VERSION ""

NS_ :

BS_:

BU_:

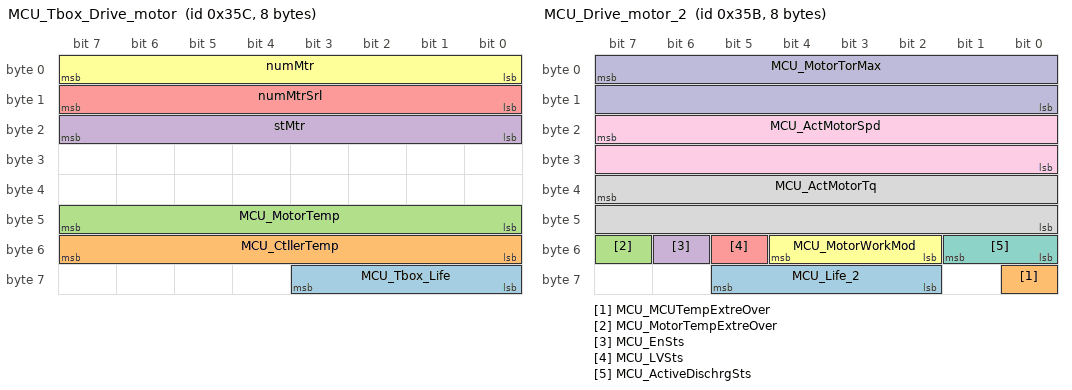
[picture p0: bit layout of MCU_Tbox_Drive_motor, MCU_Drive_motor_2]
BO_ 860 MCU_Tbox_Drive_motor: 8 Vector__XXX
 SG_ MCU_Tbox_Life : 59|4@0+ (1,0) [0|15] "" Vector__XXX
 SG_ MCU_CtllerTemp : 55|8@0+ (1,-40) [-40|210] "" Vector__XXX
 SG_ MCU_MotorTemp : 47|8@0+ (1,-40) [-40|210] "" Vector__XXX
 SG_ stMtr : 23|8@0+ (1,0) [0|255] "" Vector__XXX
 SG_ numMtrSrl : 15|8@0+ (1,0) [0|250] "" Vector__XXX
 SG_ numMtr : 7|8@0+ (1,0) [0|250] "" Vector__XXX

BO_ 859 MCU_Drive_motor_2: 8 Vector__XXX
 SG_ MCU_Life_2 : 61|4@0+ (1,0) [0|15] "" Vector__XXX
 SG_ MCU_MCUTempExtreOver : 56|1@0+ (1,0) [0|1] "" Vector__XXX
 SG_ MCU_MotorTempExtreOver : 55|1@0+ (1,0) [0|1] "" Vector__XXX
 SG_ MCU_EnSts : 54|1@0+ (1,0) [0|1] "" Vector__XXX
 SG_ MCU_LVSts : 53|1@0+ (1,0) [0|1] "" Vector__XXX
 SG_ MCU_MotorWorkMod : 52|3@0+ (1,0) [0|7] "" Vector__XXX
 SG_ MCU_ActiveDischrgSts : 49|2@0+ (1,0) [0|3] "" Vector__XXX
 SG_ MCU_ActMotorTq : 39|16@0+ (0.1,-3000) [-3000|3000] "Nm" Vector__XXX
 SG_ MCU_ActMotorSpd : 23|16@0+ (1,-12000) [-12000|12000] "RPM" Vector__XXX
 SG_ MCU_MotorTorMax : 7|16@0+ (0.1,-3000) [-3000|3000] "Nm" Vector__XXX

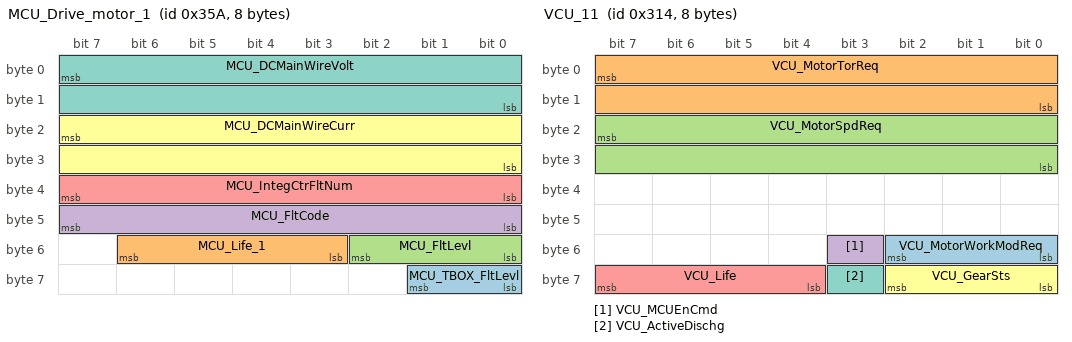
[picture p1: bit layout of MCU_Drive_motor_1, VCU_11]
BO_ 858 MCU_Drive_motor_1: 8 Vector__XXX
 SG_ MCU_TBOX_FltLevl : 57|2@0+ (1,0) [0|3] "" Vector__XXX
 SG_ MCU_Life_1 : 54|4@0+ (1,0) [0|15] "" Vector__XXX
 SG_ MCU_FltLevl : 50|3@0+ (1,0) [0|7] "" Vector__XXX
 SG_ MCU_FltCode : 47|8@0+ (1,0) [0|250] "" Vector__XXX
 SG_ MCU_IntegCtrFltNum : 39|8@0+ (1,0) [0|250] "" Vector__XXX
 SG_ MCU_DCMainWireCurr : 23|16@0+ (0.1,-1000) [-1000|1000] "A" Vector__XXX
 SG_ MCU_DCMainWireVolt : 7|16@0+ (0.1,0) [0|1000] "V" Vector__XXX

BO_ 788 VCU_11: 8 Vector__XXX
 SG_ VCU_MotorWorkModReq : 50|3@0+ (1,0) [0|7] "" Vector__XXX
 SG_ VCU_MotorTorReq : 7|16@0+ (0.1,-3000) [-3000|3000] "Nm" Vector__XXX
 SG_ VCU_MotorSpdReq : 23|16@0+ (1,-12000) [-12000|12000] "RPM" Vector__XXX
 SG_ VCU_MCUEnCmd : 51|1@0+ (1,0) [0|1] "" Vector__XXX
 SG_ VCU_Life : 63|4@0+ (1,0) [0|15] "" Vector__XXX
 SG_ VCU_GearSts : 58|3@0+ (1,0) [0|7] "" Vector__XXX
 SG_ VCU_ActiveDischg : 59|1@0+ (1,0) [0|1] "" Vector__XXX

CM_ SG_ 860 MCU_CtllerTemp "驱动电机温度";
CM_ SG_ 860 MCU_MotorTemp "驱动电机温度";
CM_ SG_ 860 stMtr "驱动电机状态";
CM_ SG_ 860 numMtrSrl "驱动电机序号";
CM_ SG_ 860 numMtr "驱动电机个数";
CM_ SG_ 859 MCU_MCUTempExtreOver "MCU过温故障";
CM_ SG_ 859 MCU_MotorTempExtreOver "驱动电机过温故障";
CM_ SG_ 859 MCU_EnSts "MCU使能状态";
CM_ SG_ 859 MCU_LVSts "MCU低压上电状态";
CM_ SG_ 859 MCU_MotorWorkMod "电机工作模式反馈";
CM_ SG_ 859 MCU_ActiveDischrgSts "MCU主动放电状态";
CM_ SG_ 859 MCU_ActMotorTq "电机实际转矩";
CM_ SG_ 859 MCU_ActMotorSpd "电机转速";
CM_ SG_ 859 MCU_MotorTorMax "电机最大可用转矩";
CM_ SG_ 858 MCU_TBOX_FltLevl "MCU故障等级(控制器温度/电机温度)
";
CM_ SG_ 858 MCU_FltLevl "MCU故障等级";
CM_ SG_ 858 MCU_FltCode "MCU故障代码";
CM_ SG_ 858 MCU_IntegCtrFltNum "MCU故障个数";
CM_ SG_ 858 MCU_DCMainWireCurr "MCU母线电流";
CM_ SG_ 858 MCU_DCMainWireVolt "MCU母线电压";
CM_ SG_ 788 VCU_MotorWorkModReq "电机工作模式控制";
CM_ SG_ 788 VCU_MotorTorReq "电机目标转矩";
CM_ SG_ 788 VCU_MotorSpdReq "电机目标转速";
CM_ SG_ 788 VCU_MCUEnCmd "MCU使能命令";
CM_ SG_ 788 VCU_GearSts "挡位状态";
CM_ SG_ 788 VCU_ActiveDischg "主动放电命令";
BA_DEF_  "BusType" STRING ;
BA_DEF_DEF_  "BusType" "CAN";
